AUTOSAR XML (schema 00044)
package /ComponentTypes
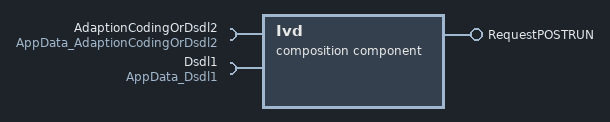
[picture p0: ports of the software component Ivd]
  composition sw component type Ivd
    provide port RequestPOSTRUN: nonqueued-sender-com-spec{data-element=Request, init-value=1}, provided-interface=RequestPOSTRUN
    require port AdaptionCodingOrDsdl2: client-com-spec=Data, required-interface=AppData_AdaptionCodingOrDsdl2
    require port Dsdl1: required-com-specs=[AdrRange, Data], required-interface=AppData_Dsdl1
    4 x component:
      ShA: type=ShA
      NvA: type=NvA
      DiagA: type=DiagA
      AppDataA: type=AppDataA
    delegate ShA.RequestPOSTRUN <-> outer port RequestPOSTRUN
    delegate AppDataA.AdaptionCodingOrDsdl2 <-> outer port AdaptionCodingOrDsdl2
    delegate AppDataA.Dsdl1 <-> outer port Dsdl1
